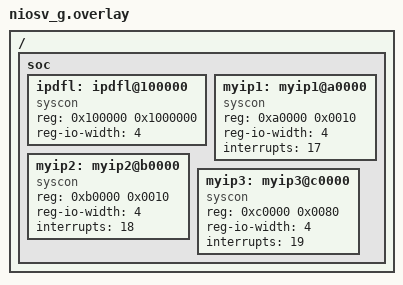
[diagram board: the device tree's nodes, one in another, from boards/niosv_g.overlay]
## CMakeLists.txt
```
# SPDX-License-Identifier: Apache-2.0

if( BUILD_FPGA_IP_ACCESS_MODE STREQUAL ZEPHYR)
    cmake_minimum_required(VERSION 3.20.0)
    find_package(Zephyr REQUIRED HINTS $ENV{ZEPHYR_BASE})

    add_compile_definitions(ZEPHYR_FPGA_IP_ACCESS)

    option(TEST_INT "Enable Interrupt Test" OFF)
    if (TEST_INT)
        add_compile_definitions(ZEPHYR_UNIT_TEST_INT)
    endif()

    zephyr_include_directories(
	    ../common/inc
	    inc
        ${CMAKE_BINARY_DIR}/include
    )

    FILE(GLOB api_sources src/*.c)
    FILE(GLOB cmn_sources ../common/src/*.c)

    zephyr_library_named(fpga_ip_access_cmn)
    zephyr_library_sources(${cmn_sources})
    zephyr_link_libraries(fpga_ip_access_cmn)

    zephyr_library_named(fpga_ip_access_api)
    zephyr_library_sources(${api_sources})
    zephyr_link_libraries(fpga_ip_access_api)

    add_custom_target(version_cmn
    ${CMAKE_COMMAND} -D SRC=${CMAKE_CURRENT_SOURCE_DIR}/../common/inc/intel_fpga_api_cmn_version.h.in
                   -D DST=${CMAKE_BINARY_DIR}/include/intel_fpga_api_cmn_version.h
                   -P ${CMAKE_CURRENT_SOURCE_DIR}/../common/cmake/version.cmake
    )
 
    add_dependencies(zephyr_interface version_cmn)

    if (TEST)
	    target_sources(app PRIVATE test/main.c ${api_sources})
    endif()

endif()
```

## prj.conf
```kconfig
CONFIG_GETOPT=y
CONFIG_GETOPT_LONG=y
CONFIG_MINIMAL_LIBC_MALLOC_ARENA_SIZE=2048
CONFIG_DYNAMIC_INTERRUPTS=y
CONFIG_APPLICATION_DEFINED_SYSCALL=y
CONFIG_POSIX_API=y
CONFIG_SYSCON=y
```

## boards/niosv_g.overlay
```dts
/ {
        soc {

                ipdfl: ipdfl@100000 {
                    compatible = "syscon", "fpga-ip-access-dfl";
                    reg = <0x100000 0x1000000>;
                    reg-io-width = <4>;
                    status = "okay";
                };

                myip1: myip1@a0000 {
                    compatible = "syscon", "fpga-ip-access";
                    reg = <0xa0000 0x0010>;
                    reg-io-width = <4>;
                    interrupts = <17>;
                    status = "okay";
                };

                myip2: myip2@b0000 {
                    compatible = "syscon", "fpga-ip-access";
                    reg = <0xb0000 0x0010>;
                    reg-io-width = <4>;
                    interrupts = <18>;
                    status = "okay";
                };

                myip3: myip3@c0000 {
                    compatible = "syscon", "fpga-ip-access";
                    reg = <0xc0000 0x0080>;
                    reg-io-width = <4>;
                    interrupts = <19>;
                    status = "okay";
                };
        };
};
```

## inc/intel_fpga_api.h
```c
// Copyright(c) 2023, Intel Corporation
//
// Redistribution  and  use  in source  and  binary  forms,  with  or  without
// modification, are permitted provided that the following conditions are met:
//
// * Redistributions of  source code  must retain the  above copyright notice,
//   this list of conditions and the following disclaimer.
// * Redistributions in binary form must reproduce the above copyright notice,
//   this list of conditions and the following disclaimer in the documentation
//   and/or other materials provided with the distribution.
// * Neither the name  of Intel Corporation  nor the names of its contributors
//   may be used to  endorse or promote  products derived  from this  software
//   without specific prior written permission.
//
// THIS SOFTWARE IS PROVIDED BY THE COPYRIGHT HOLDERS AND CONTRIBUTORS "AS IS"
// AND ANY EXPRESS OR IMPLIED WARRANTIES, INCLUDING,  BUT NOT LIMITED TO,  THE
// IMPLIED WARRANTIES OF  MERCHANTABILITY AND FITNESS FOR A PARTICULAR PURPOSE
// ARE DISCLAIMED.  IN NO EVENT  SHALL THE COPYRIGHT OWNER  OR CONTRIBUTORS BE
// LIABLE  FOR  ANY  DIRECT,  INDIRECT,  INCIDENTAL,  SPECIAL,  EXEMPLARY,  OR
// CONSEQUENTIAL  DAMAGES  (INCLUDING,  BUT  NOT LIMITED  TO,  PROCUREMENT  OF
// SUBSTITUTE GOODS OR SERVICES;  LOSS OF USE,  DATA, OR PROFITS;  OR BUSINESS
// INTERRUPTION)  HOWEVER CAUSED  AND ON ANY THEORY  OF LIABILITY,  WHETHER IN
// CONTRACT,  STRICT LIABILITY,  OR TORT  (INCLUDING NEGLIGENCE  OR OTHERWISE)
// ARISING IN ANY WAY OUT OF THE USE OF THIS SOFTWARE,  EVEN IF ADVISED OF THE
// POSSIBILITY OF SUCH DAMAGE.

#pragma once

#include "intel_fpga_api_cmn_msg.h"
#include "intel_fpga_api_cmn_inf.h"
#include "intel_fpga_api_zephyr.h"
```

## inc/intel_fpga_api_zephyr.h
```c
// Copyright(c) 2023, Intel Corporation
//
// Redistribution  and  use  in source  and  binary  forms,  with  or  without
// modification, are permitted provided that the following conditions are met:
//
// * Redistributions of  source code  must retain the  above copyright notice,
//   this list of conditions and the following disclaimer.
// * Redistributions in binary form must reproduce the above copyright notice,
//   this list of conditions and the following disclaimer in the documentation
//   and/or other materials provided with the distribution.
// * Neither the name  of Intel Corporation  nor the names of its contributors
//   may be used to  endorse or promote  products derived  from this  software
//   without specific prior written permission.
//
// THIS SOFTWARE IS PROVIDED BY THE COPYRIGHT HOLDERS AND CONTRIBUTORS "AS IS"
// AND ANY EXPRESS OR IMPLIED WARRANTIES, INCLUDING,  BUT NOT LIMITED TO,  THE
// IMPLIED WARRANTIES OF  MERCHANTABILITY AND FITNESS FOR A PARTICULAR PURPOSE
// ARE DISCLAIMED.  IN NO EVENT  SHALL THE COPYRIGHT OWNER  OR CONTRIBUTORS BE
// LIABLE  FOR  ANY  DIRECT,  INDIRECT,  INCIDENTAL,  SPECIAL,  EXEMPLARY,  OR
// CONSEQUENTIAL  DAMAGES  (INCLUDING,  BUT  NOT LIMITED  TO,  PROCUREMENT  OF
// SUBSTITUTE GOODS OR SERVICES;  LOSS OF USE,  DATA, OR PROFITS;  OR BUSINESS
// INTERRUPTION)  HOWEVER CAUSED  AND ON ANY THEORY  OF LIABILITY,  WHETHER IN
// CONTRACT,  STRICT LIABILITY,  OR TORT  (INCLUDING NEGLIGENCE  OR OTHERWISE)
// ARISING IN ANY WAY OUT OF THE USE OF THIS SOFTWARE,  EVEN IF ADVISED OF THE
// POSSIBILITY OF SUCH DAMAGE.

#pragma once

#include <stdbool.h>
#include <stdint.h>
#include <stdarg.h>
#include "intel_fpga_platform_zephyr.h"
#include "intel_fpga_api_cmn_inf.h"
#include <zephyr/drivers/syscon.h>

#ifdef __cplusplus
extern "C" {
#endif

static inline void *fpga_zephyr_get_base_address(FPGA_MMIO_INTERFACE_HANDLE handle)
{
#pragma GCC diagnostic push
#pragma GCC diagnostic ignored "-Wint-to-pointer-cast"
#pragma GCC diagnostic ignored "-Wpointer-to-int-cast"
    return (void *)zephyr_dfl_base_addr_decoder((uint64_t)common_fpga_interface_info_vec_at(handle)->base_address);
#pragma GCC diagnostic pop
}

static inline uint8_t fpga_read_8(FPGA_MMIO_INTERFACE_HANDLE handle, uint32_t offset)
{
	return *((volatile uint8_t *)fpga_zephyr_get_base_address(handle) + offset);
}

static inline void fpga_write_8(FPGA_MMIO_INTERFACE_HANDLE handle, uint32_t offset, uint8_t value)
{
	*((volatile uint8_t *)fpga_zephyr_get_base_address(handle) + offset) = value;
}

static inline uint16_t fpga_read_16(FPGA_MMIO_INTERFACE_HANDLE handle, uint32_t offset)
{
	return *((volatile uint16_t *)((volatile uint8_t *)fpga_zephyr_get_base_address(handle) + offset));
}

static inline void fpga_write_16(FPGA_MMIO_INTERFACE_HANDLE handle, uint32_t offset, uint16_t value)
{
	*((volatile uint16_t *)((volatile uint8_t *)fpga_zephyr_get_base_address(handle) + offset)) = value;
}

static inline uint32_t fpga_read_32(FPGA_MMIO_INTERFACE_HANDLE handle, uint32_t offset)
{
    uint32_t val;
	if(common_fpga_interface_info_vec_at(handle)->dfl)
	{
		val = *((volatile uint32_t *)((volatile uint8_t *)fpga_zephyr_get_base_address(handle) + offset));
	}
	else
	{
		syscon_read_reg(common_fpga_interface_info_vec_at(handle)->dev, offset, &val);
    }
	return val;
}

static inline void fpga_write_32(FPGA_MMIO_INTERFACE_HANDLE handle, uint32_t offset, uint32_t value)
{
    if(common_fpga_interface_info_vec_at(handle)->dfl)
    {
		*((volatile uint32_t *)((volatile uint8_t *)fpga_zephyr_get_base_address(handle) + offset)) = value;
    }
	else
	{
		syscon_write_reg(common_fpga_interface_info_vec_at(handle)->dev, offset, value);
	}
}

static inline uint64_t fpga_read_64(FPGA_MMIO_INTERFACE_HANDLE handle, uint32_t offset)
{
#ifndef FPGA_PLATFORM_FORCE_64BIT_MMIO_EMULATION_WITH_32BIT
    return *((volatile uint64_t *)((volatile uint8_t *)fpga_zephyr_get_base_address(handle) + offset));
#else
    // This emulation is needed when Intel FPGA PCIe Memory Mapped Bridge IP is used to implement the PCIe function.
    // Little-endian system is assumed.
    uint64_t data = fpga_read_32(handle, offset);
    data |= (uint64_t)fpga_read_32(handle, offset + 4) << 32;

    return data;
#endif
}

static inline void fpga_write_64(FPGA_MMIO_INTERFACE_HANDLE handle, uint32_t offset, uint64_t value)
{
#ifndef FPGA_PLATFORM_FORCE_64BIT_MMIO_EMULATION_WITH_32BIT
    *((volatile uint64_t *)((volatile uint8_t *)fpga_zephyr_get_base_address(handle) + offset)) = value;
#else
    // This emulation is needed when Intel FPGA PCIe Memory Mapped Bridge IP is used to implement the PCIe function.
    // Little-endian system is assumed.
    fpga_write_32(handle, offset, (uint32_t)value);
    fpga_write_32(handle, offset + 4, (uint32_t)(value >> 32));
#endif
}

static inline void fpga_read_512(FPGA_MMIO_INTERFACE_HANDLE handle, uint32_t offset, uint8_t *value)
{
    int     i;
    for(i = 0; i < (512/64); ++i)
    {
        *((volatile uint64_t *)value) = fpga_read_64(handle, offset);
        value += 64/8;
        offset += 64/8;
    }
}

static inline void fpga_write_512(FPGA_MMIO_INTERFACE_HANDLE handle, uint32_t offset, uint8_t *value)
{
    int     i;
    for(i = 0; i < (512/64); ++i)
    {
        fpga_write_64(handle, offset, *((volatile uint64_t *)value));
        value += 64/8;
        offset += 64/8;
    }
}

void *fpga_malloc(FPGA_MMIO_INTERFACE_HANDLE handle, uint32_t size);
void fpga_free(FPGA_MMIO_INTERFACE_HANDLE handle, void *address);
FPGA_PLATFORM_PHYSICAL_MEM_ADDR_TYPE fpga_get_physical_address(void *address);

int fpga_register_isr(FPGA_INTERRUPT_HANDLE handle, FPGA_ISR isr, void *isr_context);
int fpga_enable_interrupt(FPGA_INTERRUPT_HANDLE handle);
int fpga_disable_interrupt(FPGA_INTERRUPT_HANDLE handle);

#ifdef __cplusplus
}
#endif
```

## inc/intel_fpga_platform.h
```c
// Copyright(c) 2023, Intel Corporation
//
// Redistribution  and  use  in source  and  binary  forms,  with  or  without
// modification, are permitted provided that the following conditions are met:
//
// * Redistributions of  source code  must retain the  above copyright notice,
//   this list of conditions and the following disclaimer.
// * Redistributions in binary form must reproduce the above copyright notice,
//   this list of conditions and the following disclaimer in the documentation
//   and/or other materials provided with the distribution.
// * Neither the name  of Intel Corporation  nor the names of its contributors
//   may be used to  endorse or promote  products derived  from this  software
//   without specific prior written permission.
//
// THIS SOFTWARE IS PROVIDED BY THE COPYRIGHT HOLDERS AND CONTRIBUTORS "AS IS"
// AND ANY EXPRESS OR IMPLIED WARRANTIES, INCLUDING,  BUT NOT LIMITED TO,  THE
// IMPLIED WARRANTIES OF  MERCHANTABILITY AND FITNESS FOR A PARTICULAR PURPOSE
// ARE DISCLAIMED.  IN NO EVENT  SHALL THE COPYRIGHT OWNER  OR CONTRIBUTORS BE
// LIABLE  FOR  ANY  DIRECT,  INDIRECT,  INCIDENTAL,  SPECIAL,  EXEMPLARY,  OR
// CONSEQUENTIAL  DAMAGES  (INCLUDING,  BUT  NOT LIMITED  TO,  PROCUREMENT  OF
// SUBSTITUTE GOODS OR SERVICES;  LOSS OF USE,  DATA, OR PROFITS;  OR BUSINESS
// INTERRUPTION)  HOWEVER CAUSED  AND ON ANY THEORY  OF LIABILITY,  WHETHER IN
// CONTRACT,  STRICT LIABILITY,  OR TORT  (INCLUDING NEGLIGENCE  OR OTHERWISE)
// ARISING IN ANY WAY OUT OF THE USE OF THIS SOFTWARE,  EVEN IF ADVISED OF THE
// POSSIBILITY OF SUCH DAMAGE.

#pragma once

#include "intel_fpga_platform_zephyr.h"
```

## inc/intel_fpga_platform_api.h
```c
// Copyright(c) 2023, Intel Corporation
//
// Redistribution  and  use  in source  and  binary  forms,  with  or  without
// modification, are permitted provided that the following conditions are met:
//
// * Redistributions of  source code  must retain the  above copyright notice,
//   this list of conditions and the following disclaimer.
// * Redistributions in binary form must reproduce the above copyright notice,
//   this list of conditions and the following disclaimer in the documentation
//   and/or other materials provided with the distribution.
// * Neither the name  of Intel Corporation  nor the names of its contributors
//   may be used to  endorse or promote  products derived  from this  software
//   without specific prior written permission.
//
// THIS SOFTWARE IS PROVIDED BY THE COPYRIGHT HOLDERS AND CONTRIBUTORS "AS IS"
// AND ANY EXPRESS OR IMPLIED WARRANTIES, INCLUDING,  BUT NOT LIMITED TO,  THE
// IMPLIED WARRANTIES OF  MERCHANTABILITY AND FITNESS FOR A PARTICULAR PURPOSE
// ARE DISCLAIMED.  IN NO EVENT  SHALL THE COPYRIGHT OWNER  OR CONTRIBUTORS BE
// LIABLE  FOR  ANY  DIRECT,  INDIRECT,  INCIDENTAL,  SPECIAL,  EXEMPLARY,  OR
// CONSEQUENTIAL  DAMAGES  (INCLUDING,  BUT  NOT LIMITED  TO,  PROCUREMENT  OF
// SUBSTITUTE GOODS OR SERVICES;  LOSS OF USE,  DATA, OR PROFITS;  OR BUSINESS
// INTERRUPTION)  HOWEVER CAUSED  AND ON ANY THEORY  OF LIABILITY,  WHETHER IN
// CONTRACT,  STRICT LIABILITY,  OR TORT  (INCLUDING NEGLIGENCE  OR OTHERWISE)
// ARISING IN ANY WAY OUT OF THE USE OF THIS SOFTWARE,  EVEN IF ADVISED OF THE
// POSSIBILITY OF SUCH DAMAGE.

#pragma once

#include "intel_fpga_platform_api_zephyr.h"
```

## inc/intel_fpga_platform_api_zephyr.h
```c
// Copyright(c) 2023, Intel Corporation
//
// Redistribution  and  use  in source  and  binary  forms,  with  or  without
// modification, are permitted provided that the following conditions are met:
//
// * Redistributions of  source code  must retain the  above copyright notice,
//   this list of conditions and the following disclaimer.
// * Redistributions in binary form must reproduce the above copyright notice,
//   this list of conditions and the following disclaimer in the documentation
//   and/or other materials provided with the distribution.
// * Neither the name  of Intel Corporation  nor the names of its contributors
//   may be used to  endorse or promote  products derived  from this  software
//   without specific prior written permission.
//
// THIS SOFTWARE IS PROVIDED BY THE COPYRIGHT HOLDERS AND CONTRIBUTORS "AS IS"
// AND ANY EXPRESS OR IMPLIED WARRANTIES, INCLUDING,  BUT NOT LIMITED TO,  THE
// IMPLIED WARRANTIES OF  MERCHANTABILITY AND FITNESS FOR A PARTICULAR PURPOSE
// ARE DISCLAIMED.  IN NO EVENT  SHALL THE COPYRIGHT OWNER  OR CONTRIBUTORS BE
// LIABLE  FOR  ANY  DIRECT,  INDIRECT,  INCIDENTAL,  SPECIAL,  EXEMPLARY,  OR
// CONSEQUENTIAL  DAMAGES  (INCLUDING,  BUT  NOT LIMITED  TO,  PROCUREMENT  OF
// SUBSTITUTE GOODS OR SERVICES;  LOSS OF USE,  DATA, OR PROFITS;  OR BUSINESS
// INTERRUPTION)  HOWEVER CAUSED  AND ON ANY THEORY  OF LIABILITY,  WHETHER IN
// CONTRACT,  STRICT LIABILITY,  OR TORT  (INCLUDING NEGLIGENCE  OR OTHERWISE)
// ARISING IN ANY WAY OUT OF THE USE OF THIS SOFTWARE,  EVEN IF ADVISED OF THE
// POSSIBILITY OF SUCH DAMAGE.

#pragma once

#include <stdbool.h>
#include <stdarg.h>
#include <zephyr/kernel.h>
#include <zephyr/device.h>

#ifdef __cplusplus
extern "C" {
#endif


bool fpga_platform_init(unsigned int argc, const char *argv[]);
void fpga_platform_cleanup();

/// @brief Switch to enable/disable any message printf.  By default, any message printf is disabled.
#define INTEL_FPGA_MSG_PRINTF_ENABLE  1

/// @brief Switch to enable/disable message printf of the INTEL_FPGA_MSG_PRINTF_INFO type.  By default, such type of message printf is disabled.
#define INTEL_FPGA_MSG_PRINTF_ENABLE_INFO  1

/// @brief Switch to enable/disable message printf of the INTEL_FPGA_MSG_PRINTF_WARNING type.  By default, such type of message printf is disabled.
#define INTEL_FPGA_MSG_PRINTF_ENABLE_WARNING  1

/// @brief Switch to enable/disable message printf of the INTEL_FPGA_MSG_PRINTF_ERROR type.  By default, such type of message printf is disabled.
#define INTEL_FPGA_MSG_PRINTF_ENABLE_ERROR  1

/// @brief Switch to enable/disable message printf of the INTEL_FPGA_MSG_PRINTF_DEBUG type.  By default, such type of message printf is disabled.
#define INTEL_FPGA_MSG_PRINTF_ENABLE_DEBUG  1


#ifdef __cplusplus
}
#endif
```

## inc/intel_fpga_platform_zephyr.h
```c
// Copyright(c) 2023, Intel Corporation
//
// Redistribution  and  use  in source  and  binary  forms,  with  or  without
// modification, are permitted provided that the following conditions are met:
//
// * Redistributions of  source code  must retain the  above copyright notice,
//   this list of conditions and the following disclaimer.
// * Redistributions in binary form must reproduce the above copyright notice,
//   this list of conditions and the following disclaimer in the documentation
//   and/or other materials provided with the distribution.
// * Neither the name  of Intel Corporation  nor the names of its contributors
//   may be used to  endorse or promote  products derived  from this  software
//   without specific prior written permission.
//
// THIS SOFTWARE IS PROVIDED BY THE COPYRIGHT HOLDERS AND CONTRIBUTORS "AS IS"
// AND ANY EXPRESS OR IMPLIED WARRANTIES, INCLUDING,  BUT NOT LIMITED TO,  THE
// IMPLIED WARRANTIES OF  MERCHANTABILITY AND FITNESS FOR A PARTICULAR PURPOSE
// ARE DISCLAIMED.  IN NO EVENT  SHALL THE COPYRIGHT OWNER  OR CONTRIBUTORS BE
// LIABLE  FOR  ANY  DIRECT,  INDIRECT,  INCIDENTAL,  SPECIAL,  EXEMPLARY,  OR
// CONSEQUENTIAL  DAMAGES  (INCLUDING,  BUT  NOT LIMITED  TO,  PROCUREMENT  OF
// SUBSTITUTE GOODS OR SERVICES;  LOSS OF USE,  DATA, OR PROFITS;  OR BUSINESS
// INTERRUPTION)  HOWEVER CAUSED  AND ON ANY THEORY  OF LIABILITY,  WHETHER IN
// CONTRACT,  STRICT LIABILITY,  OR TORT  (INCLUDING NEGLIGENCE  OR OTHERWISE)
// ARISING IN ANY WAY OUT OF THE USE OF THIS SOFTWARE,  EVEN IF ADVISED OF THE
// POSSIBILITY OF SUCH DAMAGE.

#pragma once

#include <stdbool.h>
#include <stdint.h>
#include <stddef.h>
#include <string.h>

#include "intel_fpga_platform_api_zephyr.h"

#ifdef __cplusplus
extern "C" {
#endif


#define FPGA_PLATFORM_MAJOR_VERSION 0
#define FPGA_PLATFORM_MINOR_VERSION 1
#define FPGA_PLATFORM_HAS_NATIVE_MMIO_READ_8
#define FPGA_PLATFORM_HAS_NATIVE_MMIO_WRITE_8
#define FPGA_PLATFORM_HAS_NATIVE_MMIO_READ_16
#define FPGA_PLATFORM_HAS_NATIVE_MMIO_WRITE_16
#define FPGA_PLATFORM_HAS_NATIVE_MMIO_READ_32
#define FPGA_PLATFORM_HAS_NATIVE_MMIO_WRITE_32
#define FPGA_PLATFORM_HAS_NATIVE_MMIO_READ_64
#define FPGA_PLATFORM_HAS_NATIVE_MMIO_WRITE_64
#define FPGA_PLATFORM_IS_ISR_CALLED_IN_THREAD

// Interrupt Thread Status Flag Definition
#define FPGA_PLATFORM_INT_THREAD_EXIT      (1<<0)

typedef void (*FPGA_ISR) ( void *isr_context );
typedef int FPGA_MMIO_INTERFACE_HANDLE;
#define FPGA_MMIO_INTERFACE_INVALID_HANDLE -1
typedef int FPGA_INTERRUPT_HANDLE;
#define FPGA_INTERRUPT_INVALID_HANDLE -1
uint64_t zephyr_dfl_base_addr_decoder(uint64_t base_addr);

typedef struct {
    uint16_t version;
    uint16_t param_id;
    size_t   data_size;   // number of param_data in bytes, this should only be modified through param_data_resize()
    uint64_t *data;       // pointer to a param_data, mutiple of 8
#ifdef DFL_WALKER_DEBUG_MODE
    uint64_t current_param_addr;
    uint64_t next_param_addr;
#endif
} FPGA_INTERFACE_PARAMETER;

typedef struct {
    uint64_t                     guid_l;        //lower 64 bits of the GUID
    uint64_t                     guid_h;        //upper 64 bits of the GUID
} FPGA_INTERFACE_GUID;

typedef struct
{
    //uint8_t                      version;       //!< Identify the version of the interface.
    //uint8_t                      mfg_id;        //!< Identify the vendor providing.
    //uint16_t                     type;          //!< Identify the type of interface.
    //uint16_t                     instance;      //!< Identify an instance of interface when this interface is instantiated multiple times in the system.
    //uint16_t                     group_id;      //!< Define a group of interfaces that support a high-level function.  One fpga ip access may be developed using such group of interfaces.
    //uint8_t                      subsystem_id;  //!< Define the subsystem scope of the group_id and instance field.

    FPGA_INTERFACE_GUID          guid;
    uint16_t                     instance_id;       //!< Identify an instance of interface when this interface is instantiated multiple times in the system.
    uint16_t                     group_id;          //!< Define a group of interfaces that support a high-level function.  One fpga ip access may be developed using such group of interfaces.
    size_t                       num_of_parameters; //!< Define the array size of parameters 
    FPGA_INTERFACE_PARAMETER     *parameters;       //!< Point to parameter array
    int                          dfh_parent;        //!< Index to the FPGA_INTERFACE_INFO of the parent; -1 if there is no parent

    // Platform specific private members
    void                         *base_address;  //!< Define the base address to be used by MMIO functions
    uint16_t                     interrupt;      //!< interrupt assignment
    bool                         is_mmio_opened;
    bool                         is_interrupt_opened;
    bool                         interrupt_enable;
    FPGA_ISR                     isr_callback;
    void                         *isr_context;
    int32_t                      irq;
    const struct device          *dev;
    bool                         dfl;
    void                         *dfl_base_address;
} FPGA_INTERFACE_INFO;

typedef void * FPGA_PLATFORM_PHYSICAL_MEM_ADDR_TYPE;

#ifdef __cplusplus
}
#endif
```

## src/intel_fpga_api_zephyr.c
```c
// Copyright(c) 2023, Intel Corporation
//
// Redistribution  and  use  in source  and  binary  forms,  with  or  without
// modification, are permitted provided that the following conditions are met:
//
// * Redistributions of  source code  must retain the  above copyright notice,
//   this list of conditions and the following disclaimer.
// * Redistributions in binary form must reproduce the above copyright notice,
//   this list of conditions and the following disclaimer in the documentation
//   and/or other materials provided with the distribution.
// * Neither the name  of Intel Corporation  nor the names of its contributors
//   may be used to  endorse or promote  products derived  from this  software
//   without specific prior written permission.
//
// THIS SOFTWARE IS PROVIDED BY THE COPYRIGHT HOLDERS AND CONTRIBUTORS "AS IS"
// AND ANY EXPRESS OR IMPLIED WARRANTIES, INCLUDING,  BUT NOT LIMITED TO,  THE
// IMPLIED WARRANTIES OF  MERCHANTABILITY AND FITNESS FOR A PARTICULAR PURPOSE
// ARE DISCLAIMED.  IN NO EVENT  SHALL THE COPYRIGHT OWNER  OR CONTRIBUTORS BE
// LIABLE  FOR  ANY  DIRECT,  INDIRECT,  INCIDENTAL,  SPECIAL,  EXEMPLARY,  OR
// CONSEQUENTIAL  DAMAGES  (INCLUDING,  BUT  NOT LIMITED  TO,  PROCUREMENT  OF
// SUBSTITUTE GOODS OR SERVICES;  LOSS OF USE,  DATA, OR PROFITS;  OR BUSINESS
// INTERRUPTION)  HOWEVER CAUSED  AND ON ANY THEORY  OF LIABILITY,  WHETHER IN
// CONTRACT,  STRICT LIABILITY,  OR TORT  (INCLUDING NEGLIGENCE  OR OTHERWISE)
// ARISING IN ANY WAY OUT OF THE USE OF THIS SOFTWARE,  EVEN IF ADVISED OF THE
// POSSIBILITY OF SUCH DAMAGE.

#include <stdbool.h>
#include <stdint.h>
#include <zephyr/irq.h>

#include "intel_fpga_api_zephyr.h"
#include "intel_fpga_api_cmn_msg.h"

void *fpga_malloc(FPGA_MMIO_INTERFACE_HANDLE handle, uint32_t size)
{
    fpga_throw_runtime_exception("fpga_malloc", __FILE__, __LINE__, "Current platform doesn't support such feature.");

    return NULL;
}

void fpga_free(FPGA_MMIO_INTERFACE_HANDLE handle, void *address)
{
    fpga_throw_runtime_exception("fpga_free", __FILE__, __LINE__, "Current platform doesn't support such feature.");
}

FPGA_PLATFORM_PHYSICAL_MEM_ADDR_TYPE fpga_get_physical_address(void *address)
{
    fpga_throw_runtime_exception("fpga_get_physical_address", __FILE__, __LINE__, "Current platform doesn't support such feature.");

    return 0;
}
int fpga_register_isr(FPGA_INTERRUPT_HANDLE handle, FPGA_ISR isr, void *isr_context)
{
    int ret = -1;
    /* TBD need to go through api */
    if (handle < common_fpga_interface_info_vec_size() )
    {
        ret = 0;
        if(common_fpga_interface_info_vec_at(handle)->isr_callback != NULL)
        {
            ret = 1;
        }

	    if(common_fpga_interface_info_vec_at(handle)->irq > -1 && isr != NULL)
	    {
            common_fpga_interface_info_vec_at(handle)->isr_callback = isr;
            common_fpga_interface_info_vec_at(handle)->isr_context = isr_context;
            uint32_t irq = common_fpga_interface_info_vec_at(handle)->irq;
	        irq_connect_dynamic(irq, 1, (void *)isr, isr_context, 0);
	    }
	    else
	    {
	        ret = -1;
	    }
    }
    return ret;
}

int fpga_enable_interrupt(FPGA_INTERRUPT_HANDLE handle)
{
    int ret    = -1;
    if (handle < common_fpga_interface_info_vec_size() )
    {
        if(common_fpga_interface_info_vec_at(handle)->interrupt_enable == false && common_fpga_interface_info_vec_at(handle)->irq >=0)
        {
            irq_enable(common_fpga_interface_info_vec_at(handle)->irq);
            common_fpga_interface_info_vec_at(handle)->interrupt_enable = true;
            ret = 0;
        }
    }
    return ret;
}

int fpga_disable_interrupt(FPGA_INTERRUPT_HANDLE handle)
{
    int ret = -1;
    if (handle < common_fpga_interface_info_vec_size() )
    {
        if(common_fpga_interface_info_vec_at(handle)->interrupt_enable == true && common_fpga_interface_info_vec_at(handle)->irq >=0)
	    {
            irq_disable(common_fpga_interface_info_vec_at(handle)->irq);
	    common_fpga_interface_info_vec_at(handle)->interrupt_enable = false;
	    ret = 0;
	    }
    }
    return ret;
}
```

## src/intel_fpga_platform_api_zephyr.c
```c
// Copyright(c) 2023, Intel Corporation
//
// Redistribution  and  use  in source  and  binary  forms,  with  or  without
// modification, are permitted provided that the following conditions are met:
//
// * Redistributions of  source code  must retain the  above copyright notice,
//   this list of conditions and the following disclaimer.
// * Redistributions in binary form must reproduce the above copyright notice,
//   this list of conditions and the following disclaimer in the documentation
//   and/or other materials provided with the distribution.
// * Neither the name  of Intel Corporation  nor the names of its contributors
//   may be used to  endorse or promote  products derived  from this  software
//   without specific prior written permission.
//
// THIS SOFTWARE IS PROVIDED BY THE COPYRIGHT HOLDERS AND CONTRIBUTORS "AS IS"
// AND ANY EXPRESS OR IMPLIED WARRANTIES, INCLUDING,  BUT NOT LIMITED TO,  THE
// IMPLIED WARRANTIES OF  MERCHANTABILITY AND FITNESS FOR A PARTICULAR PURPOSE
// ARE DISCLAIMED.  IN NO EVENT  SHALL THE COPYRIGHT OWNER  OR CONTRIBUTORS BE
// LIABLE  FOR  ANY  DIRECT,  INDIRECT,  INCIDENTAL,  SPECIAL,  EXEMPLARY,  OR
// CONSEQUENTIAL  DAMAGES  (INCLUDING,  BUT  NOT LIMITED  TO,  PROCUREMENT  OF
// SUBSTITUTE GOODS OR SERVICES;  LOSS OF USE,  DATA, OR PROFITS;  OR BUSINESS
// INTERRUPTION)  HOWEVER CAUSED  AND ON ANY THEORY  OF LIABILITY,  WHETHER IN
// CONTRACT,  STRICT LIABILITY,  OR TORT  (INCLUDING NEGLIGENCE  OR OTHERWISE)
// ARISING IN ANY WAY OUT OF THE USE OF THIS SOFTWARE,  EVEN IF ADVISED OF THE
// POSSIBILITY OF SUCH DAMAGE.

#include <errno.h>
#include <stddef.h>
#include <ctype.h>
#include <limits.h>
#include <stdarg.h>
#include <stdio.h>
#include <stdlib.h>
#include <string.h>
#include <getopt.h>

#include <sys/types.h>
#include <sys/stat.h>
#include <fcntl.h>

#include "intel_fpga_api_cmn_msg.h"
#include "intel_fpga_api_cmn_dfl.h"
#include "intel_fpga_api_zephyr.h"
#include "intel_fpga_platform_zephyr.h"
#include "intel_fpga_platform_api_zephyr.h"

static size_t s_zephyr_addr_span = 0;
static int s_zephyr_single_component_mode = 0;
static size_t s_zephyr_start_addr = 0;
static void *s_zephyr_mmap_ptr = NULL;

static uint64_t s_zephyr_dfl_addr = 0;
static bool s_zephyr_dfl_found = false;

//static int8_t s_zephyr_irq = -1;
//static const struct device *s_zephyr_dev = NULL;
//static bool zephyr_open_driver();
#ifdef ZEPHYR_UNIT_TEST_SW_MODEL_MODE
static bool zephyr_create_unit_test_sw_model();
#endif
static bool zephyr_scan_interfaces();
static void zephyr_parse_args(unsigned int argc, const char *argv[]);
static bool zephyr_validate_args();
static long parse_integer_arg(const char *name);
extern char *optarg;
extern int optind, optopt;

struct dev_info {
    const struct device *dev;
    uint64_t base_addr;
    uint32_t size;
    int32_t irq;
	uint32_t type;
};

#define FPGA_IP_ACCESS_DEV(node_id) \
    { .dev = DEVICE_DT_GET(node_id), \
      .base_addr = (uint64_t)DT_REG_ADDR(node_id), \
      .size = DT_REG_SIZE(node_id), \
      COND_CODE_1(DT_IRQ_HAS_IDX(node_id, 0), \
       (.irq = DT_IRQN(node_id)), \
       (.irq = -1)), \
       .type = 0, \
       IF_ENABLED(DT_NODE_HAS_COMPAT(node_id, fpga_ip_access_dfl), (.type =2,)) \
       IF_ENABLED(DT_NODE_HAS_COMPAT(node_id, fpga_ip_access), (.type =1,)) \
},

static const struct dev_info fpga_ip_access_dev_table[] = {
    DT_FOREACH_STATUS_OKAY(syscon, FPGA_IP_ACCESS_DEV)
};

bool fpga_platform_init(unsigned int argc, const char *argv[])
{
    bool        is_args_valid;
    bool        ret = false;

    zephyr_parse_args(argc, argv);
    is_args_valid = zephyr_validate_args();

    if (is_args_valid)
    {
#ifndef ZEPHYR_UNIT_TEST_SW_MODEL_MODE
        if(zephyr_scan_interfaces() == false)
            goto all_ret;
#else
        if(zephyr_create_unit_test_sw_model() == false)
            goto all_ret;
#endif
        ret = true;
    }
all_ret:
    return ret;
}

void fpga_platform_cleanup()
{
    // Re-initialize local variables.
    s_zephyr_start_addr = 0;
    s_zephyr_addr_span = 0;
    s_zephyr_single_component_mode = 0;
    s_zephyr_mmap_ptr = NULL;

    if (common_fpga_interface_info_vec_size() > 0)
    {
#ifdef ZEPHYR_UNIT_TEST_SW_MODEL_MODE
        free(common_fpga_interface_info_vec_at(0)->base_address);
#endif
        common_fpga_interface_info_vec_resize(0);
    }

    errno = -1;  //  -1 is a valid return on success.  Some function, such as strtol(), doesn't set errno upon successful return.

    fpga_msg_printf( FPGA_MSG_PRINTF_DEBUG, "Completed fpga_platform_cleanup" );
}

void zephyr_parse_args(unsigned int argc, const char *argv[])
{
    static struct option long_options[] =
        {
            {"address-span",		required_argument, 	0, 				's'}, //For future UNIT_TEST_SW_MODEL_MODE purpose
            {0, 0, 0, 0}
	};

    int option_index = 0;
    int c;

    while(1)
    {
        c = getopt_long(argc, (char * const*)argv, "s:", long_options, &option_index);

        if (c == -1)
        {
            break;
        }

        switch(c)
        {
            case 's':
                s_zephyr_addr_span = parse_integer_arg("Address span");
                break;
        }
    }
}

long parse_integer_arg( const char *name )
{
    long ret = 0;

    bool is_all_digit = true;
    char *p;
    typedef int (*DIGIT_TEST_FN) ( int c );
    DIGIT_TEST_FN is_acceptabl_digit;
    if(optarg[0] == '0' && (optarg[1] == 'x' || optarg[1] == 'X'))
    {
        is_acceptabl_digit = isxdigit;
        optarg += 2;    // trim the "0x" portion
    }
    else
    {
        is_acceptabl_digit = isdigit;
    }

    for(p = optarg; (*p) != '\0'; ++p)
    {
        if(!is_acceptabl_digit(*p))
        {
            is_all_digit = false;
            break;
        }
    }

    if ( is_acceptabl_digit == isxdigit )
    {
        optarg -= 2;  // restore the "0x" portion
    }

    if (is_all_digit)
    {
        if (sizeof(size_t) <= sizeof(long))
        {
            ret = (size_t)strtol(optarg, NULL, 0);
            if (errno == ERANGE)
            {
                ret = 0;
                fpga_msg_printf( FPGA_MSG_PRINTF_ERROR, "%s value is too big. %s is provided; maximum accepted is %ld", name, optarg, LONG_MAX );
            }
        }
        else
        {
            long span, span_c;
            span = strtol(optarg, NULL, 0);
            if (errno == ERANGE)
            {
                ret = 0;
                fpga_msg_printf( FPGA_MSG_PRINTF_ERROR, "%s value is too big. %s is provided; maximum accepted is %ld", name, optarg, LONG_MAX );
            }
            else
            {
                ret = (size_t)span;
                span_c = ret;
                if (span != span_c)
                {
                    fpga_msg_printf( FPGA_MSG_PRINTF_ERROR, "%s value is too big. %s is provided; maximum accepted is %ld", name, optarg, (size_t)-1 );
                    ret = 0;
                }
            }
        }
    }
    else
    {
        fpga_msg_printf( FPGA_MSG_PRINTF_ERROR, "Invalid argument value type is provided. A integer value is expected. %s is provided.", optarg );
    }

    return ret;
}

bool zephyr_validate_args()
{
    bool ret =false;

#ifdef ZEPHYR_UNIT_TEST_SW_MODEL_MODE
    ret = s_zephyr_addr_span > 0;

    if (!ret)
    {
        if ( s_zephyr_addr_span == 0 )
        {
            fpga_msg_printf( FPGA_MSG_PRINTF_ERROR, "No valid address span value is provided using the argument, --address-span." );
        }
    }
#else
    ret = true;
#endif
    return ret;
}

uint64_t zephyr_dfl_base_addr_decoder(uint64_t base_addr)
{
    return(base_addr - s_zephyr_dfl_addr);
}

bool zephyr_scan_interfaces()
{
    bool ret = false;
    uint32_t index = 0;
    uint8_t  discovered_dev_n = ARRAY_SIZE(fpga_ip_access_dev_table);
    void *first_dfh_addr = NULL;

    if( discovered_dev_n > 0)
    {
        if(s_zephyr_single_component_mode)
        {
            common_fpga_interface_info_vec_resize(1);
#pragma GCC diagnostic push
#pragma GCC diagnostic ignored "-Wpointer-to-int-cast"
#pragma GCC diagnostic ignored "-Wint-to-pointer-cast"
            common_fpga_interface_info_vec_at(0)->base_address = (void *)(fpga_ip_access_dev_table[0].base_addr + s_zephyr_start_addr);
#pragma GCC diagnostic pop
            common_fpga_interface_info_vec_at(0)->dev = fpga_ip_access_dev_table[0].dev;
            common_fpga_interface_info_vec_at(0)->irq = fpga_ip_access_dev_table[0].irq;
            common_fpga_interface_info_vec_at(0)->is_mmio_opened = false;
            common_fpga_interface_info_vec_at(0)->is_interrupt_opened = false;

            printk("SINGLE COMPONENT MODE : Only 1 device can be used!\n");
        }
        else
        {
            for (uint32_t n = 0; n < ARRAY_SIZE(fpga_ip_access_dev_table); n++) {

				switch (fpga_ip_access_dev_table[n].type)
				{
					case 1:
						// Add new index for new device
                        // Always after DFL rom
                        index = common_fpga_interface_info_vec_size();
						common_fpga_interface_info_vec_resize(index+1);
#pragma GCC diagnostic push
#pragma GCC diagnostic ignored "-Wpointer-to-int-cast"
#pragma GCC diagnostic ignored "-Wint-to-pointer-cast"
						common_fpga_interface_info_vec_at(index)->base_address = (void *)(fpga_ip_access_dev_table[n].base_addr + s_zephyr_start_addr);
#pragma GCC diagnostic pop
						common_fpga_interface_info_vec_at(index)->dfl = false;
						common_fpga_interface_info_vec_at(index)->dev = fpga_ip_access_dev_table[n].dev;
						common_fpga_interface_info_vec_at(index)->irq = fpga_ip_access_dev_table[n].irq;
						common_fpga_interface_info_vec_at(index)->is_mmio_opened = false;
						common_fpga_interface_info_vec_at(index)->is_interrupt_opened = false;
						break;

					case 2:
                        // Assume DFL rom start at index 0
                        // Only support 1 DFL rom
                        if(s_zephyr_dfl_found == true)
                            return ret;
#pragma GCC diagnostic push
#pragma GCC diagnostic ignored "-Wint-to-pointer-cast"
                        first_dfh_addr = (void *)(fpga_ip_access_dev_table[n].base_addr + s_zephyr_start_addr);
#pragma GCC diagnostic pop
                        s_zephyr_dfl_addr = fpga_ip_access_dev_table[n].base_addr;
                        s_zephyr_dfl_found = true;
						common_dfl_scan_multi_interfaces(first_dfh_addr, zephyr_dfl_base_addr_decoder);
					break;

					default:
						break;

				}
            }
        }
        ret = true;
    }
    return ret;
}

bool zephyr_create_unit_test_sw_model()
{
    bool  ret = true;

    common_fpga_interface_info_vec_resize(1);

    common_fpga_interface_info_vec_at(0)->base_address = malloc(s_zephyr_addr_span);
    // Preset mem with all 1s
    memset(common_fpga_interface_info_vec_at(0)->base_address, 0xFF, s_zephyr_addr_span);

    return ret;
}
```
